# PIC32CZ4010CA80208 device description
Architecture: CORTEX-M7; Family: PIC32C; Series: PIC32CZCA80
Registers are 32-bit, read-write, reset 0x0 unless marked. A register's access mark holds for its fields unless they carry their own. Offsets are from the block's base; [hi:lo] are bit positions; {n}, {i} and the like mark numbered series; <NAME> marks a mode.

## FPB — Flash Patch and Breakpoint
Instances: FPB 0xE0002000
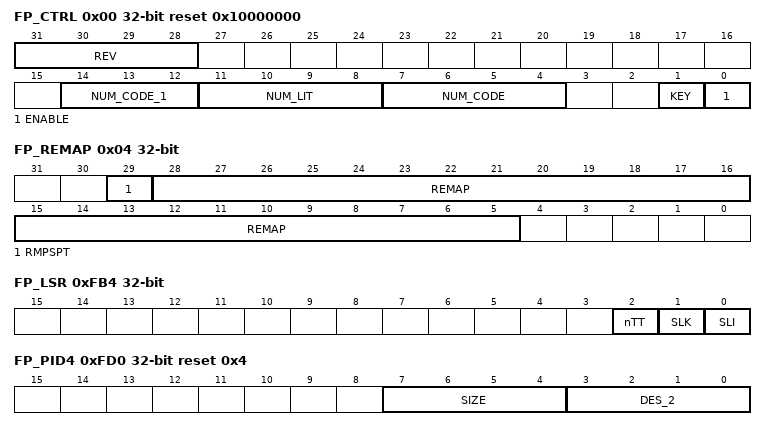
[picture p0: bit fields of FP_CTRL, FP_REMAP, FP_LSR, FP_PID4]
0x00 FP_CTRL reset 0x10000000 — Flash Patch Control Register
  [31:28] REV — Revision
  [14:12] NUM_CODE_1 — Number of implemented code comparators bits [6:4]
  [11:8] NUM_LIT — Number of literal comparators
  [7:4] NUM_CODE — Number of implemented code comparators bits [3:0]
  [1] KEY — FP_CTRL write-enable key
  [0] ENABLE — Flash Patch global enable
0x04 FP_REMAP ro — Flash Patch Remap Register
  [29] RMPSPT — Remap supported
  [28:5] REMAP — Remap address
{0x8+4i} FP_COMP[{i}] (i=0..7) — Flash Patch Comparator Register n
  [0] BE — Breakpoint enable
  [31:1] BPADDR <BREAKPOINT> — Breakpoint address
  [31] FE <DEFAULT> — Flash Patch enable
  [28:2] FPADDR <DEFAULT> — Flash Patch address
0xFB0 FP_LAR wo reset not defined — FPB Software Lock Access Register
  [31:0] KEY — Lock access control
    0xC5ACCE55=UNLOCK (Unlock key value)
0xFB4 FP_LSR ro reset not defined — FPB Software Lock Status Register
  [2] nTT — Not thirty-two bit
  [1] SLK — Software Lock status
  [0] SLI — Software Lock implemented
0xFD0 FP_PID4 ro reset 0x4 — FP Peripheral Identification Register 4
  [7:4] SIZE — 4KB count
  [3:0] DES_2 — JEP106 continuation code
{0xFC0+4i} FP_PID{i} ro (i=5..7) — FP Peripheral Identification Register {i}
0xFE0 FP_PID0 ro — FP Peripheral Identification Register 0
  [7:0] PART_0 — Part number bits[7:0]
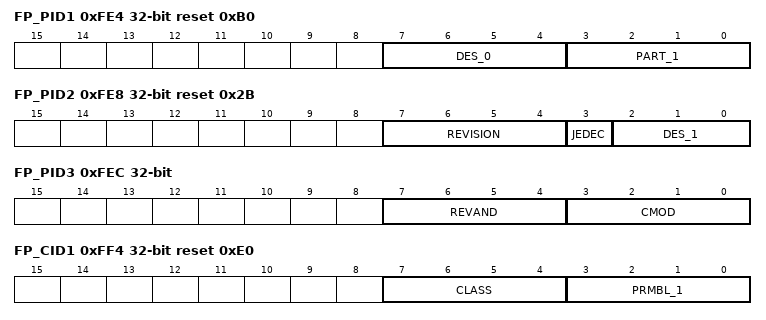
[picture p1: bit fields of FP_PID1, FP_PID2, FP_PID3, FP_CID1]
0xFE4 FP_PID1 ro reset 0xB0 — FP Peripheral Identification Register 1
  [7:4] DES_0 — JEP106 identification code bits [3:0]
  [3:0] PART_1 — Part number bits[11:8]
0xFE8 FP_PID2 ro reset 0x2B — FP Peripheral Identification Register 2
  [7:4] REVISION — Component revision
  [3] JEDEC — JEDEC assignee value is used
  [2:0] DES_1 — JEP106 identification code bits[6:4]
0xFEC FP_PID3 ro — FP Peripheral Identification Register 3
  [7:4] REVAND
  [3:0] CMOD — Customer Modified
0xFF0 FP_CID0 ro reset 0xD — FP Component Identification Register 0
  [7:0] PRMBL_0 — CoreSight component identification preamble
0xFF4 FP_CID1 ro reset 0xE0 — FP Component Identification Register 1
  [7:4] CLASS — CoreSight component class
  [3:0] PRMBL_1 — CoreSight component identification preamble
0xFF8 FP_CID2 ro reset 0x5 — FP Component Identification Register 2
  [7:0] PRMBL_2 — CoreSight component identification preamble
0xFFC FP_CID3 ro reset 0xB1 — FP Component Identification Register 3
  [7:0] PRMBL_3 — CoreSight component identification preamble

## FPU — Floating Point Unit
Instances: FPU 0xE000EF30
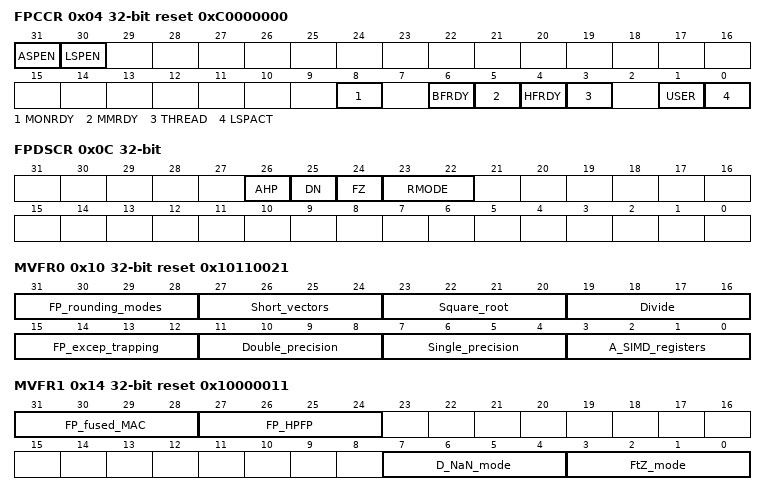
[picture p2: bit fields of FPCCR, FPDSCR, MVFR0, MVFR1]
0x04 FPCCR reset 0xC0000000 — Floating-Point Context Control Register
  [31] ASPEN, [30] LSPEN, [8] MONRDY, [6] BFRDY, [5] MMRDY, [4] HFRDY, [3] THREAD, [1] USER, [0] LSPACT
0x08 FPCAR reset not defined — Floating-Point Context Address Register
  [31:3] ADDRESS — Address for FP registers in exception stack frame
0x0C FPDSCR — Floating-Point Default Status Control Register
  [26] AHP — Default value for FPSCR.AHP
  [25] DN — Default value for FPSCR.DN
  [24] FZ — Default value for FPSCR.FZ
  [23:22] RMODE — Default value for FPSCR.RMODE
    0=RN (Round to Nearest); 1=RP (Round towards Positive Infinity); 2=RM (Round towards Negative Infinity); 3=RZ (Round towards Zero)
0x10 MVFR0 ro reset 0x10110021 — Media and FP Feature Register 0
  [31:28] FP_rounding_modes, [27:24] Short_vectors, [23:20] Square_root, [19:16] Divide, [15:12] FP_excep_trapping, [11:8] Double_precision, [7:4] Single_precision, [3:0] A_SIMD_registers
0x14 MVFR1 ro reset 0x10000011 — Media and FP Feature Register 1
  [31:28] FP_fused_MAC, [27:24] FP_HPFP, [7:4] D_NaN_mode, [3:0] FtZ_mode
0x18 MVFR2 ro reset 0x40 — Media and FP Feature Register 2

## FREQM — Frequency Meter
Instances: FREQM 0x44060000
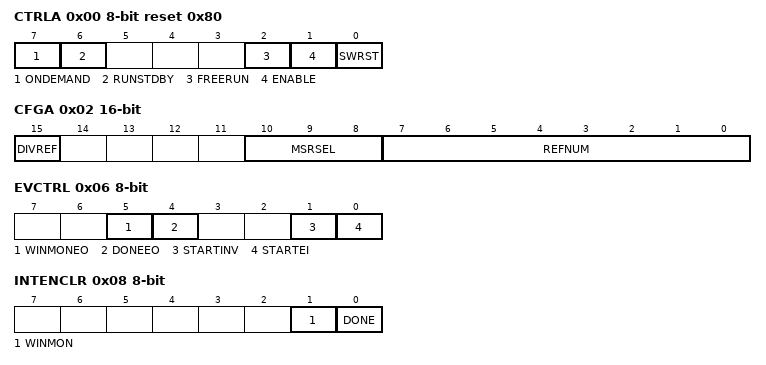
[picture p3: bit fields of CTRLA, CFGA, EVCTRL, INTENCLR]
0x00 CTRLA 8-bit reset 0x80 — Control A Register
  [7] ONDEMAND — On Demand Control
  [6] RUNSTDBY — Run In Standby
  [2] FREERUN — Free Running Mode
  [1] ENABLE
  [0] SWRST — Software Reset
0x01 CTRLB 8-bit wo — Control B Register
  [0] START — Start Measurement
0x02 CFGA 16-bit — Config A Register
  [15] DIVREF — Divide Reference Clock
    0=DIV1 (The reference clock is divided by 1); 1=DIV8 (The reference clock is divided by 8)
  [10:8] MSRSEL — Measurement Clock Selection
    0=GCLK (GCLK Input Clock); 1=CPU (CPU Input Clock)
  [7:0] REFNUM — Number of Reference Clock Cycles
0x04 CTRLC 8-bit — Control C Register
  [2:0] WINMODE — Window Monitor Mode
    0=DISABLE (No window mode (default)); 1=MODE1 (VALUE > WINLT); 2=MODE2 (VALUE < WINUT); 3=MODE3 (WINLT < VALUE < WINUT); 4=MODE4 (!(WINLT < VALUE < WINUT))
0x06 EVCTRL 8-bit — Event Control Register
  [5] WINMONEO — Window Monitor Event Out
  [4] DONEEO — Measurement Done Event Out
  [1] STARTINV — Start Measurement Event Invert Enable
  [0] STARTEI — Start Measurement Event Input Enable
0x08 INTENCLR 8-bit (atomic clear) — Interrupt Enable Clear Register
  [1] WINMON — Window Monitor Interrupt Disable
  [0] DONE — Measurement Done Interrupt Disable
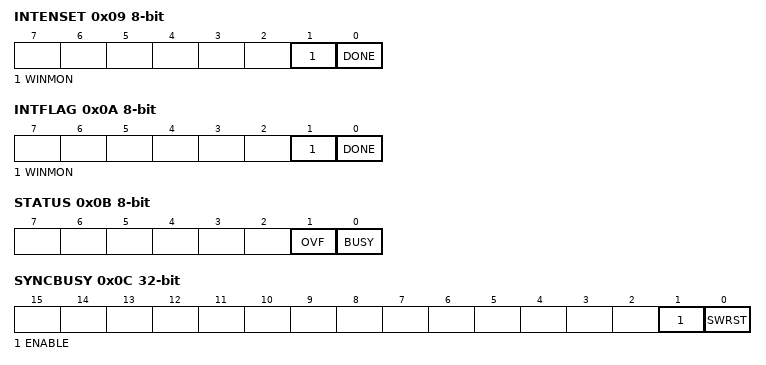
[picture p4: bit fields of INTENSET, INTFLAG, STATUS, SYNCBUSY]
0x09 INTENSET 8-bit (atomic set) — Interrupt Enable Set Register
  [1] WINMON — Window Monitor Interrupt Enable
  [0] DONE — Measurement Done Interrupt Enable
0x0A INTFLAG 8-bit (atomic clear) — Interrupt Flag Register
  [1] WINMON — Window Monitor
  [0] DONE — Measurement Done
0x0B STATUS 8-bit
  [1] OVF — Sticky Count Value Overflow
  [0] BUSY — FREQM Status
0x0C SYNCBUSY ro — Synchronization Busy Register
  [1] ENABLE
  [0] SWRST — Software Reset
0x10 VALUE ro — Count Value Register
  [23:0] VALUE — Measurement Value
0x20 WINLT — Window Monitor Lower Threshold
  [23:0] WINLT — Window Lower Threshold
0x24 WINUT — Window Monitor Upper Threshold
  [23:0] WINUT — Window Upper Threshold

## Notices in the file
Copyright (c) 2021 Microchip Technology Inc.
SPDX-License-Identifier: Apache-2.0
Licensed under the Apache License, Version 2.0 (the "License");
you may not use this file except in compliance with the License.
You may obtain a copy of the License at
http://www.apache.org/licenses/LICENSE-2.0
Unless required by applicable law or agreed to in writing, software
distributed under the License is distributed on an "AS IS" BASIS,
WITHOUT WARRANTIES OR CONDITIONS OF ANY KIND, either express or implied.
See the License for the specific language governing permissions and
limitations under the License.
